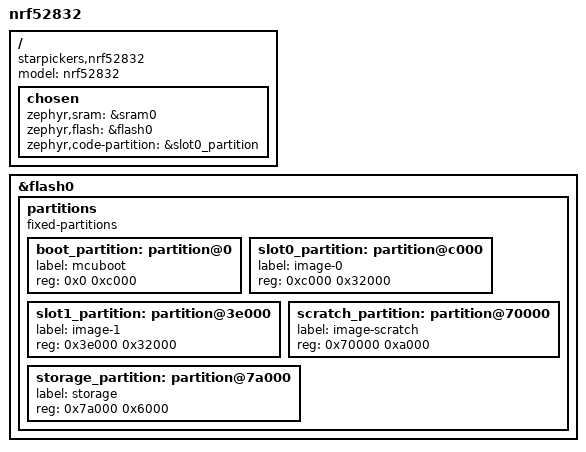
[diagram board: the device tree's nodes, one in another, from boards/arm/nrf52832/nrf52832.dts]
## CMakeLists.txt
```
cmake_minimum_required(VERSION 3.20.0)
find_package(Zephyr REQUIRED HINTS $ENV{ZEPHYR_BASE})

project(Firmware_TEST_IoT)

target_sources(app PRIVATE src/main.cpp
    src/EC21V2.cpp
    src/UARTE.cpp
    src/RTC.cpp)

target_include_directories(app PRIVATE src/)
```

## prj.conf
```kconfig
# General Configurations
CONFIG_CPP=y
CONFIG_NFCT_PINS_AS_GPIOS=y
CONFIG_GPIO_AS_PINRESET=n

# Debugging Configurations
CONFIG_CONSOLE=y
CONFIG_USE_SEGGER_RTT=y
CONFIG_RTT_CONSOLE=y
```

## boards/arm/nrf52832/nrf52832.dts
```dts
// Copyright (c) 2024 Nordic Semiconductor ASA
// SPDX-License-Identifier: Apache-2.0

/dts-v1/;
#include <nordic/nrf52832_qfaa.dtsi>

/ {
	model = "nrf52832";
	compatible = "starpickers,nrf52832";

	chosen {
		zephyr,sram = &sram0;
		zephyr,flash = &flash0;
		zephyr,code-partition = &slot0_partition;
	};
};

&flash0 {
	partitions {
		compatible = "fixed-partitions";
		#address-cells = <1>;
		#size-cells = <1>;

		boot_partition: partition@0 {
			label = "mcuboot";
			reg = <0x0 0xc000>;
		};
		slot0_partition: partition@c000 {
			label = "image-0";
			reg = <0xc000 0x32000>;
		};
		slot1_partition: partition@3e000 {
			label = "image-1";
			reg = <0x3e000 0x32000>;
		};
		scratch_partition: partition@70000 {
			label = "image-scratch";
			reg = <0x70000 0xa000>;
		};
		storage_partition: partition@7a000 {
			label = "storage";
			reg = <0x7a000 0x6000>;
		};
	};
};
```

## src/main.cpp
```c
#include <zephyr/kernel.h>
#include <EC21V2.h>
#include <UARTE.h>
#include <RTC.h>

/* GPIO Pin 설정 */
#define GPIO_LED_RED        22
#define GPIO_LED_GREEN      23
#define GPIO_LED_BLUE       24
#define GPIO_EXT_PWR        2

/* LTE 모뎀 핀 설정 */
#define GPIO_LTE_PIN_DISABLE    7
#define GPIO_LTE_PIN_WAKEUP     8
#define GPIO_LTE_PIN_PWRKEY     25
#define GPIO_LTE_PIN_RESET      26
#define GPIO_LTE_UART_RX        10
#define GPIO_LTE_UART_TX        9

// External Module Library
UARTE uarte;
EC21 lte;
RTC rtc;
EC21_DEVICE_INFO ec21_device_info;
extern bool getmes;

// External Handler
void EC21_EventHandler(uint16_t EC21_EVENT_TYPE);
void EC21_ErrorHandler(uint16_t EC21_ERROR_CODE);

// 인터럽트 핸들러
void RTC2_IRQHandler();
void GPIOTE_IRQHandler();

int main(void)
{
        // GNSS 초기화
        NRF_GPIO->DIRSET = (1 << GPIO_LED_RED) | (1 << GPIO_LED_GREEN) | (1 << GPIO_LED_BLUE);
        NRF_GPIO->OUTSET = (1 << GPIO_LED_RED) | (1 << GPIO_LED_GREEN) | (1 << GPIO_LED_BLUE);

        // 초기화 함수
        RTC_CONFIG rtc_config = {
             .channel = RTC2,
             .prescaler = 32            // 99.9Hz   
        };
        rtc.Init(rtc_config);
        rtc.setEvent(RTC_INTERRUPT_COMPARE0);
        rtc.setInterrupt(RTC_INTERRUPT_COMPARE0);
        IRQ_DIRECT_CONNECT(RTC2_IRQn, 0, RTC2_IRQHandler, 0);
        irq_enable(RTC2_IRQn);
        rtc.Start();
        
        // NFC핀을 GPIO로 변환
        NRF_UICR->NFCPINS = 0x00;

        // LTE 모뎀 초기화
        UARTE_CONFIG config_uarte = {
                .PIN_RX = GPIO_LTE_UART_RX,
                .PIN_TX = GPIO_LTE_UART_TX,
                .BAUD = UARTE_BAUDRATE_115200,
        };
        uarte.Init(config_uarte);
        EC21_CONFIG config_lte = {
                .uarte = uarte,
                .rtc = rtc,
                .pin_pwr = GPIO_LTE_PIN_PWRKEY,
                .pin_reset = GPIO_LTE_PIN_RESET,
                .pin_wakeup = GPIO_LTE_PIN_WAKEUP,
                .pin_disable = GPIO_LTE_PIN_DISABLE,
        };
        lte.Init(config_lte);
        printk("LTE modem initialized.\n");     

        // RESET핀을 GPIO로 설정
        NRF_NVMC->CONFIG = NVMC_CONFIG_WEN_Wen << NVMC_CONFIG_WEN_Pos; // Write Enable
        while (NRF_NVMC->READY == NVMC_READY_READY_Busy){}
        NRF_UICR->PSELRESET[0] = 1 << 31;
        while (NRF_NVMC->READY == NVMC_READY_READY_Busy){}
        NRF_UICR->PSELRESET[1] = 1 << 31;
        while (NRF_NVMC->READY == NVMC_READY_READY_Busy){}
        NRF_NVMC->CONFIG = NVMC_CONFIG_WEN_Ren << NVMC_CONFIG_WEN_Pos; // Read-only Enable
        while (NRF_NVMC->READY == NVMC_READY_READY_Busy){}
        
        // LTE 모뎀 Power On
        lte.Reset();
        k_msleep(200);
        lte.powerOn();

        // GPIOTE Event 및 Interrupt 설정
        // 풀업 설정
        NRF_GPIO->PIN_CNF[21] = 0x0C;
        NRF_GPIOTE->CONFIG[0] = 0x01 | (21 << 8) | (0x02 << 16);
        NRF_GPIOTE->INTENSET = 0x01;
        IRQ_DIRECT_CONNECT(GPIOTE_IRQn, 0, GPIOTE_IRQHandler, 0);
        irq_enable(GPIOTE_IRQn);

        // NVIC 활성화
        NVIC_SetPriority(GPIOTE_IRQn, 5);
        NVIC_EnableIRQ(GPIOTE_IRQn);

        printk("GPIOTE Set.\n");
        while(true){
                k_usleep(10);
        }
        return 0;
}

void EC21_EventHandler(uint16_t EC21_EVENT_TYPE){
        // EC21 이벤트 핸들러
        switch(EC21_EVENT_TYPE){
                case EC21_EVENT_POWERON:
                        // 모뎀의 전원이 켜졌을 때 동작
                        // LED 주황색으로 수정
                        printk("LTE modem power activated.\n");
                        NRF_GPIO->OUTCLR = (1 << GPIO_LED_GREEN);

                        // Echo Off
                        lte.setEcho(false);
                break;
                case EC21_EVENT_ECHO_OFF:
                        // Echo Off 이벤트 동작
                        printk("Echo Off events\n");

                        // 기본 정보 체크
                        ec21_device_info = lte.getDeviceInfo();
                        if(strlen(ec21_device_info.imei) < 1){
                                // IMEI 정보가 없으므로 읽어옴
                                printk("No IMEI information. Query IMEI.\r\n");
                                lte.getImei();
                        }
                break;
                
                case EC21_EVENT_CAPTURE_IMEI:
                        // IMEI값 취득함
                        lte.clearLastQueary();
                        ec21_device_info = lte.getDeviceInfo();
                        if(strlen(ec21_device_info.imei) < 15){
                                break;
                        }
                        printk("IMEI Captured : %s\n", ec21_device_info.imei);
                        
                        // ICCID값 존재 여부 체크
                        if(strlen(ec21_device_info.iccid) < 1){
                                // ICCID 값이 없으므로 읽어옴
                                printk("No ICCID information. Query ICCID.\r\n");
                                lte.getIccid();
                        }
                break;
                case EC21_EVENT_CAPTURE_ICCID:
                        // ICCID값 취득 이벤트
                        lte.clearLastQueary();
                        ec21_device_info = lte.getDeviceInfo();
                        if(strlen(ec21_device_info.iccid) < 20){
                                break;
                        }
                        printk("ICCID Captured : %s\n", ec21_device_info.iccid);

                        // IMSI값 존재 여부 체크
                        if(strlen(ec21_device_info.imsi) < 1){
                                // ICCID 값이 없으므로 읽어옴
                                printk("No IMSI information. Query ICCID.\r\n");
                                lte.getImsi();
                        }
                break;
                case EC21_EVENT_CAPTURE_IMSI:
                        // IMSI값 취득 이벤트
                        lte.clearLastQueary();
                        ec21_device_info = lte.getDeviceInfo();
                        if(strlen(ec21_device_info.iccid) < 20){
                                break;
                        }
                        printk("IMSI Captured : %s\n", ec21_device_info.imsi);
                break;
        }
}
void EC21_ErrorHandler(uint16_t EC21_ERROR_CODE){

}

void RTC2_IRQHandler(){
        // RTC2 IRQHandler
        if(NRF_RTC2->EVENTS_COMPARE[0] == 1){
                NRF_RTC2->EVENTS_COMPARE[0] = 0;
                NRF_UARTE0->TASKS_STOPRX = 1;
        }
}

void GPIOTE_IRQHandler(){
        // GPIOTE 핸들러 

        int cnt = 0;

        if(NRF_GPIOTE->EVENTS_IN[0] == 1){
                NRF_GPIOTE->EVENTS_IN[0] = 0;
                        /*
                        printk("AT+CFUN=1\n");
                        lte.Query("AT+CFUN=1\r\n");
                        k_busy_wait(2000000);

                        printk("AT+QGPS=1\n");
                        lte.Query("AT+QGPS=1\r\n");
                        k_busy_wait(2000000);

                        ///printk("AT+QCFG=\"band\",F,80A,80A\n");
                        ///lte.Query("AT+QCFG=\"band\",F,80A,80A\r\n");
                        ///k_busy_wait(2000000); 

                        printk("AT+COPS=4,2,\"310410\"\n");
                        lte.Query("AT+COPS=4,2,\"310410\"\r\n");
                        k_busy_wait(2000000);   

                        printk("AT+CREG=2\n");
                        lte.Query("AT+CREG=2\r\n");
                        k_busy_wait(2000000); 

                        printk("AT+QSCLK=0\n");
                        lte.Query("AT+QSCLK=0\r\n");
                        k_busy_wait(2000000);

                        //printk("AT+QCFG=\"powerclass\",1,1\n");
                        //lte.Query("AT+QCFG=\"powerclass\",1,1\r\n");
                        //k_busy_wait(2000000);

                        */
                        //AWS연결
                        printk("AT+CEREG?\n");
                        lte.Query("AT+CEREG?\r\n");
                        k_busy_wait(2000000);
                        
                        printk("AT+QENG=\"servingcell\"\n");
                        lte.Query("AT+QENG=\"servingcell\"\r\n");
                        k_busy_wait(2000000);
                        
                        printk("AT+QIACT=1\n");
                        lte.Query("AT+QIACT=1\r\n");
                        k_busy_wait(2000000);
                        
                        printk("AT+CGPADDR=1\n");
                        lte.Query("AT+CGPADDR=1\r\n");
                        k_busy_wait(2000000);
                        
                        printk("AT+QPING=1,\"a3ovp7i619ec6q-ats.iot.us-east-1.amazonaws.com\"\n");
                        lte.Query("AT+QPING=1,\"a3ovp7i619ec6q-ats.iot.us-east-1.amazonaws.com\"\r\n");
                        k_busy_wait(4000000);
                        
                        printk("AT+QFLST=\"*\"\n");
                        lte.Query("AT+QFLST=\"*\"\r\n");
                        k_busy_wait(2000000);
                        
                        printk("AT+QMTCFG=\"recv/mode\",0,0,1\n");
                        lte.Query("AT+QMTCFG=\"recv/mode\",0,0,1\r\n");
                        k_busy_wait(2000000);
                        
                        printk("AT+QMTCFG=\"ssl\",0,1,2\n");
                        lte.Query("AT+QMTCFG=\"ssl\",0,1,2\r\n");
                        k_busy_wait(2000000);
                        
                        printk("AT+QSSLCFG=\"cacert\",2,\"cacert.pem\"\n");
                        lte.Query("AT+QSSLCFG=\"cacert\",2,\"cacert.pem\"\r\n");
                        k_busy_wait(2000000);
                        
                        printk("AT+QSSLCFG=\"clientcert\",2,\"client.pem\"\n");
                        lte.Query("AT+QSSLCFG=\"clientcert\",2,\"client.pem\"\r\n");
                        k_busy_wait(2000000);
                        
                        printk("AT+QSSLCFG=\"clientkey\",2,\"user_key.pem\"\n");
                        lte.Query("AT+QSSLCFG=\"clientkey\",2,\"user_key.pem\"\r\n");
                        k_busy_wait(2000000);
                        
                        printk("AT+QSSLCFG=\"seclevel\",2,2\n");
                        lte.Query("AT+QSSLCFG=\"seclevel\",2,2\r\n");
                        k_busy_wait(2000000);
                        
                        printk("AT+QSSLCFG=\"sslversion\",2,4\n");
                        lte.Query("AT+QSSLCFG=\"sslversion\",2,4\r\n");
                        k_busy_wait(2000000);

                        printk("AT+QSSLCFG=\"ciphersuite\",2,0xFFFF\n");
                        lte.Query("AT+QSSLCFG=\"ciphersuite\",2,0xFFFF\r\n");
                        k_busy_wait(2000000);
                        
                        printk("AT+QSSLCFG=\"ignorelocaltime\",2,1\n");
                        lte.Query("AT+QSSLCFG=\"ignorelocaltime\",2,1\r\n");
                        k_busy_wait(2000000);
                        
                        printk("AT+QMTOPEN=0,\"a3ovp7i619ec6q-ats.iot.us-east-1.amazonaws.com\",8883\n");
                        lte.Query("AT+QMTOPEN=0,\"a3ovp7i619ec6q-ats.iot.us-east-1.amazonaws.com\",8883\r\n");
                        k_busy_wait(2000000);
                        
                        printk("AT+QMTCONN=0,\"smartKit001\"\n");
                        lte.Query("AT+QMTCONN=0,\"smartKit001\"\r\n");
                        k_busy_wait(2000000);

                        //연결 완료
                        printk("AWS Connected\n");

                        printk("AT+QMTPUBEX=0,1,1,0,\"aws/smartKit001/data/report/message\",23\n");
                        lte.Query("AT+QMTPUBEX=0,1,1,0,\"aws/smartKit001/data/report/message\",23\r\n");
                        k_busy_wait(2000000);
                        
                        printk("{\"message\": \"TEST\"}\n");
                        lte.Query("{\"message\": \"TEST\"}\r\n");
                        k_busy_wait(2000000);
                        
                        //송신 테스트 완료
                        printk("AWS message sended\n");

                        // 저전력 모드로 진입
                        //NRF_UART0->TASKS_STOPTX = 1; // UART 송신 중지
                        //NRF_UART0->TASKS_STOPRX = 1; // UART 수신 중지
                        //NRF_UART0->ENABLE = 0; // UART 비활성화

                        printk("Low power mode starting...\n");

                        /*
                        printk("AT+QCFG=\"powerclass\",1,0\n");
                        lte.Query("AT+QCFG=\"powerclass\",1,0\r\n");
                        k_busy_wait(2000000);
                        */

                        NRF_SPI0->ENABLE = 0; // SPI 비활성화
                        printk("SPI unactivated\n");

                        NRF_TWI0->ENABLE = 0; // TWI(I2C) 비활성화
                        printk("TWI unactivated\n");

                        NRF_SAADC->ENABLE = 0; // ADC 비활성화
                        printk("ADC unactivated\n");

                        NRF_TIMER0->TASKS_STOP = 1; // 타이머0 중지
                        printk("Timer0 unactivated\n");

                        NRF_TIMER1->TASKS_STOP = 1; // 타이머1 중지
                        printk("Timer1 unactivated\n");

                        NRF_TIMER2->TASKS_STOP = 1; // 타이머2 중지
                        printk("Timer2 unactivated\n");

                        // 저전력 모드 활성화
                        NRF_POWER->TASKS_LOWPWR = 1;
                        printk("TASK_LOWPWR\n");

                        /*
                        printk("AT+QGPSEND\n");
                        lte.Query("AT+QGPSEND\r\n");
                        k_busy_wait(2000000);

                        printk("AT+CREG=0\n");
                        lte.Query("AT+CREG=0\r\n");
                        k_busy_wait(2000000);

                        printk("AT+COPS=0\n");
                        lte.Query("AT+COPS=0\r\n");
                        k_busy_wait(2000000);

                        printk("AT+QCFG=\"band\",F,1,1\n");
                        lte.Query("AT+QCFG=\"band\",F,1,1\r\n");
                        k_busy_wait(2000000); 
                        */

                         // LTE 및 GNSS 저전력 모드 활성화
                        printk("AT+QSCLK=1\n");
                        lte.Query("AT+QSCLK=1\r\n"); // 저전력 모드 활성화 명령어
                        k_busy_wait(2000000);

                        //lte.Query("AT+QGPSCFG=\"gnssconfig\",0\r\n"); // GNSS 저전력 모드 활성화
                        //k_busy_wait(2000000);
                        //printk("21\n");
                        printk("AT+QGPS=1\n");
                        printk("GNSS init\n");
                        lte.Query("AT+QGPS=1\r\n");//GNSS 초기화
                        k_busy_wait(2000000); 

                        printk("AT+QGPSEND\n");
                        printk("GNSS unactivated\n");
                        lte.Query("AT+QGPSEND\r\n"); // GNSS 비활성화
                        k_busy_wait(2000000);

                        printk("Low power mode on\n");

                        while (cnt<10)
                        {
                                printk("Enter Loop %d\n",cnt);
                                lte.Query("AT+QMTSUB=0,1,\"aws/smartKit001/data/report/message\",1\r\n");
                                k_busy_wait(10000000);
                                cnt++;
                                if(getmes == true){
                                        printk("Message interrupted!\n");
                                        break;
                                }
                        }
                        getmes = false;
                        
                        cnt = 0;

                        printk("Low Power mode exiting...\n");
                
                     // 외부 신호에 의해 정상 모드로 복귀
                        //NRF_UART0->TASKS_STOPTX = 1; // UART 송신 중지
                        //NRF_UART0->TASKS_STOPRX = 1; // UART 수신 중지
                        //NRF_UART0->ENABLE = 1; // UART 활성화
                        //NRF_UART0->TASKS_STARTRX = 1; // UART 수신 시작
                        //NRF_UART0->TASKS_STARTTX = 1; // UART 송신 시작
                        NRF_SPI0->ENABLE = 1; // SPI 활성화
                        printk("SPI activated\n");
                        
                        NRF_TWI0->ENABLE = 1; // TWI(I2C) 활성화
                        printk("TWI activated\n");

                        NRF_SAADC->ENABLE = 1; // ADC 활성화
                        printk("ADC activated\n");

                        NRF_TIMER0->TASKS_START = 1; // 타이머0 시작
                        printk("Timer0 activated\n");

                        NRF_TIMER1->TASKS_START = 1; // 타이머1 시작
                        printk("Timer1 activated\n");

                        NRF_TIMER2->TASKS_START = 1; // 타이머2 시작
                        printk("Timer2 activated\n");


                        printk("AT+QCFG=\"powerclass\",1,0\n");
                        lte.Query("AT+QCFG=\"powerclass\",1,0\r\n");

                        // LTE 및 GNSS 정상 모드 복귀
                        printk("AT+QSCLK=0\n");
                        lte.Query("AT+QSCLK=0\r\n"); // 저전력 모드 해제 명령어
                        k_busy_wait(2000000);
                        
                        printk("AT+QGPS=1\n");
                        printk("GNSS activated\n");
                        lte.Query("AT+QGPS=1\r\n"); // GNSS 활성화
                        k_busy_wait(2000000);

                        printk("Low power mode off\n");
        }
}
```

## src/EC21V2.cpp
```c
#include <EC21V2.h>

/* Global Variables */
static uint8_t rxBuffer[255] = {0};
char EC21::lastQuery[255] = {0};
uint16_t EC21::error_code = 0;
char Hello[6]="Hello";
bool getmes = false;

/* Global Functions */
EC21_CONFIG EC21::CONFIG;
EC21_DEVICE_INFO device_info;
extern void EC21_EventHandler(uint16_t EC21_EVENT_TYPE);
extern void EC21_ErrorHandler(uint16_t EC21_ERROR_CODE);

/* EC21 초기화 함수 */
void EC21::Init(EC21_CONFIG ec21_config){
    // 설정값 초기화 및 복사
    memset(&CONFIG, 0x00, sizeof(CONFIG));
    memcpy(&CONFIG, &ec21_config, sizeof(ec21_config));
    
    // GPIO 활성화
    NRF_GPIO->DIRSET = (1 << CONFIG.pin_pwr) | (1 << CONFIG.pin_reset) | (1 << CONFIG.pin_disable) | (1 << CONFIG.pin_wakeup);

    // UARTE 초기화
    CONFIG.uarte.setInterrupt(UARTE_INTERRUPT_RXDRDY | UARTE_INTERRUPT_ENDRX | UARTE_INTERRUPT_RXTO);
    CONFIG.uarte.setShorts(UARTE_SHORTS_ENDRX_STARTRX);
    IRQ_DIRECT_CONNECT(UARTE0_UART0_IRQn, 0, UARTE_IRQHandler, 0);
    irq_enable(UARTE0_UART0_IRQn);
    NRF_UARTE0->RXD.PTR = (uint32_t)rxBuffer;
    CONFIG.uarte.startRx(255);
}

bool EC21::Query(const char *cmd, ...){
    char temp[255] = {0};
    va_list ap;
    va_start(ap, cmd);
    vsprintf(temp, cmd, ap);
    va_end(ap);
    
    // 현재 명령어 저장
    if(strncmp(temp, "A/", 2) != 0){
        memset(lastQuery, 0x00, 255);
        strcpy(lastQuery, temp);
    }
    CONFIG.uarte.Write((uint8_t *)temp, strlen(temp));
    return true;
}

void EC21::powerOn(){
    // 모뎀 파워 온
    NRF_GPIO->OUTSET = (1 << CONFIG.pin_pwr);
    k_busy_wait(200000);
    NRF_GPIO->OUTCLR = (1 << CONFIG.pin_pwr);
}

void EC21::Reset(){
    // 모뎀 리셋
    NRF_GPIO->OUTSET = (1 << CONFIG.pin_reset);
    k_busy_wait(200000);
    NRF_GPIO->OUTCLR = (1 << CONFIG.pin_reset);
}

void EC21::retryQuery(){
    // 직전 명령어 재시도
    Query("A/\r\n");
}

void EC21::getSimStatus(){
    // SIM 상태 쿼리
    Query("AT+CPIN?\r\n");
}

void EC21::UARTE_IRQHandler(){
    if(NRF_UARTE0->EVENTS_RXDRDY == 1){
        NRF_UARTE0->EVENTS_RXDRDY = 0;
        CONFIG.rtc.setCompare(RTC_COMPARE0, CONFIG.rtc.getCounter() + UARTE_TIMEOUT);
    }
    if(NRF_UARTE0->EVENTS_ENDRX == 1){
        NRF_UARTE0->EVENTS_ENDRX = 0;
        printk("%s\n", rxBuffer); //주석 해제 처리
        if (strstr((char *)rxBuffer,Hello)!=NULL)
        {
            getmes = true;
        }
        
        parseCommand((const char *)rxBuffer);
        memset(rxBuffer, 0x00, 255);
    }
    if(NRF_UARTE0->EVENTS_RXTO == 1){
        
        NRF_UARTE0->EVENTS_RXTO = 0;
        NRF_UARTE0->TASKS_FLUSHRX = 1;
        printk("EVENTS_RXTO\n");
    }
}

void EC21::parseCommand(const char *cmd){
    // 파싱 함수
    char *temp_ptr, *temp;

    temp = strtok_r((char *)cmd, "\r\n", &temp_ptr);
    while(temp != NULL){
        printk("Temp : %s\r\n", temp);
        
        if(strncmp(temp, "+QIND: \"POWER\",1", 15) == 0){
            // Power On 이벤트
            EC21_EventHandler(EC21_EVENT_POWERON);
        }else if(strncmp(temp, "RDY", 3) == 0){
            // Power On 이벤트
            EC21_EventHandler(EC21_EVENT_POWERON);
        }else if(strncmp(temp, "ATE1", 4) == 0){
            // Echo on 이벤트
            EC21_EventHandler(EC21_EVENT_ECHO_ON);
        }else if(strncmp(temp, "+QIND: PB DONE", 14) == 0){
            // Strange
            //EC21_EventHandler(EC21_EVENT_SIM_NORMAL);
        }else if(strncmp(temp, "ATE0", 4) == 0){
            // Echo on 이벤트
            EC21_EventHandler(EC21_EVENT_ECHO_OFF);
        }else if(strncmp(temp, "+CPIN: READY", 12) == 0){
            // USIM 인식 확인
            EC21_EventHandler(EC21_EVENT_SIM_NORMAL);
        }else if(strncmp(temp, "+CPIN: NOT INSERTED", 19) == 0){
            // USIM 인식 확인
            EC21_EventHandler(EC21_EVENT_POWERON);
        }else if(strncmp(temp, "+CME", 4) == 0){
            // CME 에러 체크
            temp = strtok_r(temp, " ", &temp_ptr);
            temp = strtok_r(NULL, " ", &temp_ptr);
            temp = strtok_r(NULL, "\r\n", &temp_ptr);
            error_code = atoi(temp);
            EC21_ErrorHandler(error_code);
        }else if(strncmp(temp, "+QCCID", 6) == 0){
            // ICCID 값 캡쳐 및 저장
            temp = strtok_r(temp, " ", &temp_ptr);
            temp = strtok_r(NULL, "\r\n", &temp_ptr);
            strcpy(device_info.iccid, temp);
            EC21_EventHandler(EC21_EVENT_CAPTURE_ICCID);
        }else if((strncmp(temp, "+CREG", 5) == 0) && (strncmp(lastQuery, "AT+CREG?", 8) == 0)){
            // 네트워크 등록 체크
            temp = strtok_r(temp, ",", &temp_ptr);
            temp = strtok_r(NULL, "\r\n", &temp_ptr);
            uint8_t netStatus = atoi(temp);
            switch(netStatus){
                case 1:
                    EC21_EventHandler(EC21_EVENT_NETWORK_REGISTERED);
                break;
                case 2:
                    EC21_EventHandler(EC21_EVENT_NETWORK_NOT_REGISTERED);
                break;
                case 3:
                    EC21_EventHandler(EC21_EVENT_NETWORK_REGISTRATION_DENIED);
                break;
                case 4:
                    EC21_EventHandler(EC21_EVENT_NETWORK_REGISTRATION_UNKNOWN);
                break;
                case 5:
                    EC21_EventHandler(EC21_EVENT_NETWORK_REGISTERED_ROAMING);
                break;
                default:
                    EC21_EventHandler(EC21_EVENT_NETWORK_NOT_REGISTERED);
                break;
            }
        }else if(strncmp(temp, "+QLTS", 5) == 0){
            // 시스템 날짜 및 시간 캡쳐
            // 읽은 날짜 및 시간을 Unix epoch 값으로 변환
            struct tm t;
            temp = strtok_r(temp, "\"", &temp_ptr);
            temp = strtok_r(NULL, "/", &temp_ptr);
            t.tm_year = atoi(temp)-1900;
            temp = strtok_r(NULL, "/", &temp_ptr);
            t.tm_mon = atoi(temp)-1;
            temp = strtok_r(NULL, ",", &temp_ptr);
            t.tm_mday = atoi(temp);
            temp = strtok_r(NULL, ":", &temp_ptr);
            t.tm_hour = atoi(temp);
            temp = strtok_r(NULL, ":", &temp_ptr);
            t.tm_min = atoi(temp);
            temp = strtok_r(NULL, "+", &temp_ptr);
            t.tm_sec = atoi(temp);
            device_info.epoch = timeutil_timegm64(&t);
            EC21_EventHandler(EC21_EVENT_CAPTURE_SYSTIME);
        }else if(strncmp(temp, "+QHTTPPOST", 10) == 0){
            // QHTTPPOST Check
            temp = strtok_r(temp, ":", &temp_ptr);
            temp = strtok_r(NULL, ",", &temp_ptr);
            int16_t returnCode = atoi(temp);
            temp = strtok_r(NULL, ",", &temp_ptr);
            int16_t responseCode = atoi(temp);
            temp = strtok_r(NULL, ",", &temp_ptr);
            int16_t contentsLength = atoi(temp);
            if(returnCode == 702){
                // HTTP Timeout
                EC21_ErrorHandler(EC21_HTTP_ERROR_GENERAL);
            }else if(returnCode == 703){
                // HTTP Busy
                EC21_ErrorHandler(EC21_CME_ERROR_HTTP_BUSY);
            }else if(returnCode == 704){
                // HTTP UART Busy
                EC21_ErrorHandler(EC21_HTTP_ERROR_GENERAL);
            }else if(responseCode == 403){
                // 서버 주소 에러
                EC21_ErrorHandler(EC21_HTTP_RESPONSE_403);
            }else if(contentsLength == 8){
                // 재부팅용
                EC21_EventHandler(EC21_EVENT_REMOTE_REBOOT);
            }else{
                EC21_EventHandler(EC21_EVENT_QHTTPPOST);
            }
        }else if(strncmp(temp, "OK", 2) == 0){
            // OK 명령 파싱
            if(strcmp(lastQuery, "AT+QIACT=1\r\n") == 0){
                // Activate PDP Context 명령
                EC21_EventHandler(EC21_EVENT_QI_ACTIVATED);
            }else if(strncmp(lastQuery, "AT+QHTTPCFG", 11) == 0){
                // QHTTPCFG 설정 OK
                EC21_EventHandler(EC21_EVENT_QHTTPCFG_SET);
            }else if(strncmp(lastQuery, "http", 4) == 0){
                // http url 설정
                EC21_EventHandler(EC21_EVENT_QHTTPURL_SET);
            }else if(strncmp(lastQuery, "AT+QIDEACT", 10) == 0){
                Query("AT+QIACT=1\r\n");
            }else{
                //temp = strtok_r(NULL, ":", &temp_ptr);
                //printk("Query OK : %s\r\n", temp);
            }
        }else if(strncmp(temp, "CONNECT", 7) == 0){
            // CONNECT 명령 파싱
            if(strncmp(lastQuery, "AT+QHTTPURL", 11) == 0){
                Query("%s\r\n", device_info.urls);
            }else if(strncmp(lastQuery, "AT+QHTTPPOST", 12) == 0){
                EC21_EventHandler(EC21_EVENT_QHTTPPOST_SET);
            }else{
                //printk("Query Connect : %s", temp);
            }
        }else if(strncmp(temp, "+QIND: \"FOTA\",\"START\"", 21) == 0){
            // FOTA START 관련 처리
            EC21_EventHandler(EC21_EVENT_FOTA_START);
        }else if(strncmp(temp, "+QIND: \"FOTA\",\"END\"", 17) == 0){
            // FOTA END 관련 처리
            EC21_EventHandler(EC21_EVENT_FOTA_END);
        }else if(strncmp(temp, "+QIND: \"FOTA\"", 13) == 0){
            // FOTA PROGRESS 관련 처리
            EC21_EventHandler(EC21_EVENT_FOTA_PROGRESS);
        }else if(strncmp(temp, "+QKTFOTA: 200", 13) == 0){
            // KT FOTA 처리
            EC21_EventHandler(EC21_EVENT_FOTA_KT);
        }else if(strncmp(temp, "+QURC: \"DMC-APN\"", 16) == 0){
            // APN 변경시 동작
            EC21_EventHandler(EC21_EVENT_APN_CHANGED);
        }else if(strncmp(temp, "ERROR", 5) == 0){
            // 에러 동작
            EC21_ErrorHandler(EC21_GENERAL_ERROR);
        }else{
            // 별도의 AT 커맨드 표기 없는 리턴 값 분류
            if((strcmp(lastQuery, "AT+GSN\r\n") == 0) && (strncmp(temp, "86", 2) == 0)){
                // IMEI 쿼리
                temp = strtok_r(temp, "\r\n", &temp_ptr);
                strcpy(device_info.imei, temp);
                EC21_EventHandler(EC21_EVENT_CAPTURE_IMEI);
            }else if((strcmp(lastQuery, "AT+CIMI\r\n") == 0) && (temp[0] >= 0x30 && temp[0] <= 0x39)){
                // IMSI 쿼리
                temp = strtok_r(temp, "\r\n", &temp_ptr);
                strcpy(device_info.imsi, temp);
                EC21_EventHandler(EC21_EVENT_CAPTURE_IMSI);
            }else{
            //printk("TEST : %s", temp);
            }
        }
        temp = strtok_r(NULL, "\r\n", &temp_ptr);
    };
}

uint16_t EC21::getErrorCode(){
    return error_code;
}

EC21_DEVICE_INFO EC21::getDeviceInfo(){
    // ICCID, IMEI, IMSI 값 읽어오는 함수
    return device_info;
}

tm EC21::getDatetime(uint64_t time_elapsed){
    // 시간 계산
    time_t temp = device_info.epoch + time_elapsed;
    struct tm output = {0};
    gmtime_r(&temp, &output);
    return output;
}

void EC21::getIccid(){
    // ICCID 값 쿼리 함수
    Query("AT+QCCID\r\n");
}
void EC21::getImei(){
    // IMEI 값 쿼리 함수
    Query("AT+GSN\r\n");
}
void EC21::getImsi(){
    // IMSI 값 쿼리 함수
    Query("AT+CIMI\r\n");
}

void EC21::getNetworkDatetime(){
    // 시스템 날짜 및 시간 쿼리 함수
    Query("AT+QLTS=2\r\n");
}

void EC21::setEcho(bool enable){
    if(enable){
        Query("ATE1\r\n");
    }else{
        Query("ATE0\r\n");
    }
}

void EC21::setHttpBody(){
    // HTTP Body 형식 지정
    Query("AT+QHTTPCFG=\"contenttype\",4\r\n");
}

void EC21::setHttpUrls(const char *urls, ...){
    // HTTP Endpoint 설정
    memset(device_info.urls, 0x00, 255);
    va_list ap;
    va_start(ap, urls);
    vsprintf(device_info.urls, urls, ap);
    va_end(ap);

    if(strncmp(device_info.urls, "http://", 7) == 0){
        // URL 설정 쿼리
        Query("AT+QHTTPURL=%d\r\n", strlen(device_info.urls));
    }else if(strncmp(device_info.urls, "https://", 8) == 0){
        // URL 설정 쿼리
        Query("AT+QHTTPURL=%d\r\n", strlen(device_info.urls));
    }else{
        printk("Wrong URL set.\r\n");
    }
}

void EC21::setHttpPost(uint16_t data_length){
    // HTTP Post 보내는 함수
    Query("AT+QHTTPPOST=%d,%d,%d\r\n", data_length, EC21_TIMEOUT, EC21_TIMEOUT);
}

void EC21::enablePDP(){
    // Activate PDP Context
    Query("AT+QIACT=1\r\n");
}
void EC21::disablePDP(){
    // Deactivate PDP Context
    Query("AT+QIDEACT=1\r\n");
}

void EC21::checkNetworkRegistration(){
    // 네트워크 등록 체크
    Query("AT+CREG?\r\n");
}

void EC21::clearDeviceInfo(){
    // 장치 정보 초기화
    memset(device_info.iccid, 0x00, sizeof(char *));
    memset(device_info.imei, 0x00, sizeof(char *));
    memset(device_info.imsi, 0x00, sizeof(char *));
    memset(lastQuery, 0x00, 255);
}

void EC21::clearLastQueary(){
    memset(lastQuery, 0x00, 255);
}
```

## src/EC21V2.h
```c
/*
        EC21 Series Module Library V2
        Author : Seonguk Jeong
        Created at : 2024-05-02
        Updated at : 2024-05-02
        Target : Quectel EC21
*/
#include <UARTE.h>
#include <RTC.h>
#include <stdlib.h>
#include <stdio.h>
#include <time.h>
#include <zephyr/sys/timeutil.h>

/* EC21 Modem Event */
#define EC21_EVENT_POWERON                          0x0001
#define EC21_EVENT_POWEROFF                         0x0002
#define EC21_EVENT_SIM_NORMAL                       0x0003
#define EC21_EVENT_SIM_ERROR                        0x0004
#define EC21_EVENT_ECHO_ON                          0x0005
#define EC21_EVENT_ECHO_OFF                         0x0006
#define EC21_EVENT_CAPTURE_ICCID                    0x0007
#define EC21_EVENT_CAPTURE_IMEI                     0x0008
#define EC21_EVENT_CAPTURE_IMSI                     0x0009
#define EC21_EVENT_CAPTURE_SYSTIME                  0x000A
#define EC21_EVENT_QI_ACTIVATED                     0x000B
#define EC21_EVENT_QI_DEACTIVATED                   0x000C
#define EC21_EVENT_QHTTPCFG_SET                     0x000D
#define EC21_EVENT_QHTTPURL_SET                     0x000E
#define EC21_EVENT_QHTTPPOST_SET                    0x000F
#define EC21_EVENT_QHTTPPOST                        0x0010
#define EC21_EVENT_NETWORK_NOT_REGISTERED           0x0011
#define EC21_EVENT_NETWORK_REGISTERED               0x0012
#define EC21_EVENT_NETWORK_REGISTRATION_DENIED      0x0013
#define EC21_EVENT_NETWORK_REGISTRATION_UNKNOWN     0x0014
#define EC21_EVENT_NETWORK_REGISTERED_ROAMING       0x0015
#define EC21_EVENT_FOTA_START                       0x0016
#define EC21_EVENT_FOTA_PROGRESS                    0x0017
#define EC21_EVENT_FOTA_END                         0x0018
#define EC21_EVENT_FOTA_KT                          0x0019
#define EC21_EVENT_APN_CHANGED                      0x0020
#define EC21_EVENT_REMOTE_REBOOT                    0x0FFF

/* EC21 CME Error Code */
#define EC21_CME_ERROR_SIM_NOT_INSERTED             10
#define EC21_CME_ERROR_SIM_PIN_REQUIRED             11
#define EC21_CME_ERROR_SIM_PUK_REQUIRED             13
#define EC21_CME_ERROR_SIM_FAILURE                  14
#define EC21_CME_ERROR_SIM_BUSY                     15
#define EC21_CME_ERROR_SIM_WRONG                    16
#define EC21_HTTP_RESPONSE_403                      403
#define EC21_HTTP_ERROR_GENERAL                     700
#define EC21_CME_ERROR_HTTP_UNKNOWN                 701
#define EC21_CME_ERROR_HTTP_BUSY                    703
#define EC21_CME_ERROR_HTTP_DNS_ERROR               714
#define EC21_CME_ERROR_HTTP_CONNECT_ERROR           716
#define EC21_HTTP_ERROR_TIMEOUT                     702
#define EC21_HTTP_ERROR_BUSY                        703
#define EC21_GENERAL_ERROR                          900

/* EC21 기본 설정 */
#define UARTE_TIMEOUT 50
#define EC21_TIMEOUT 5

struct EC21_CONFIG{
    UARTE uarte;
    RTC rtc;
    uint8_t pin_pwr;
    uint8_t pin_reset;
    uint8_t pin_wakeup;
    uint8_t pin_disable;
};
typedef struct _EC21_DEVICE_INFO{
    char imei[16] = {0};
    char imsi[16] = {0};
    char iccid[21] = {0};
    uint64_t epoch = 0;
    char urls[255] = {0};
}EC21_DEVICE_INFO;
class EC21{
    private:
        static void UARTE_IRQHandler();
        static EC21_CONFIG CONFIG;
        static uint16_t error_code;
        static char lastQuery[255];
        static void parseCommand(const char *cmd);
    public:
        void Init(EC21_CONFIG ec21_config);
        void powerOn();
        void Reset();
        void retryQuery();
        void getSimStatus();
        uint16_t getErrorCode();
        EC21_DEVICE_INFO getDeviceInfo();
        tm getDatetime(uint64_t time_elapsed);
        void getIccid();
        void getImei();
        void getImsi();
        void getNetworkDatetime();
        void setEcho(bool enable);
        void setHttpBody();
        void setHttpUrls(const char *urls, ...);
        void setHttpPost(uint16_t data_length);
        void enablePDP();
        void disablePDP();
        void checkNetworkRegistration();
        void clearDeviceInfo();
        void clearLastQueary();
        static bool Query(const char *cmd, ...);
        
};
```

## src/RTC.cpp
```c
#include "RTC.h"

void RTC::Init(RTC_CONFIG CONFIG){
    // Low frequency clock 활성화 체크
	if(!(NRF_CLOCK->LFCLKSTAT >> 16) & 0x01){
		NRF_CLOCK->LFCLKSRC = CLOCK_LFCLKSRC_SRC_Xtal;
		NRF_CLOCK->TASKS_LFCLKSTART = 0x01;
		while(!NRF_CLOCK->EVENTS_LFCLKSTARTED){}
	}
    switch(CONFIG.channel){
        case RTC0:
            NRF_RTC0->TASKS_CLEAR = 1;
		    NRF_RTC0->TASKS_STOP = 1;
		    NRF_RTC0->PRESCALER = CONFIG.prescaler;
            break;
        case RTC1:
            NRF_RTC1->TASKS_CLEAR = 1;
		    NRF_RTC1->TASKS_STOP = 1;
		    NRF_RTC1->PRESCALER = CONFIG.prescaler;
            break;
        case RTC2:
            NRF_RTC2->TASKS_CLEAR = 1;
		    NRF_RTC2->TASKS_STOP = 1;
		    NRF_RTC2->PRESCALER = CONFIG.prescaler;
            break;
        default:
            break;
    }
    // 설정 구조체 저장
    memcpy(&CONF, &CONFIG, sizeof(CONFIG));
}

void RTC::Start(){
    switch(CONF.channel){
        case RTC0:
            NRF_RTC0->TASKS_START = 1;
            break;
        case RTC1:
            NRF_RTC1->TASKS_START = 1;
            break;
        case RTC2:
            NRF_RTC2->TASKS_START = 1;
            break;
        default:
            break;
    }
}
void RTC::Stop(){
    switch(CONF.channel){
        case RTC0:
            NRF_RTC0->TASKS_STOP = 1;
            NRF_RTC0->TASKS_CLEAR = 1;
            break;
        case RTC1:
            NRF_RTC1->TASKS_STOP = 1;
            NRF_RTC1->TASKS_CLEAR = 1;
            break;
        case RTC2:
            NRF_RTC2->TASKS_STOP = 1;
            NRF_RTC2->TASKS_CLEAR = 1;
            break;
        default:
            break;
    }
}
void RTC::setInterrupt(uint32_t interrupt){
    switch(CONF.channel){
        case RTC0:
            NRF_RTC0->INTENSET = interrupt;
            NVIC_SetPriority(RTC0_IRQn, 5);
	        NVIC_EnableIRQ(RTC0_IRQn);
            break;
        case RTC1:
            NRF_RTC1->INTENSET = interrupt;
            NVIC_SetPriority(RTC1_IRQn, 5);
	        NVIC_EnableIRQ(RTC1_IRQn);
            break;
        case RTC2:
            NRF_RTC2->INTENSET = interrupt;
            NVIC_SetPriority(RTC2_IRQn, 5);
	        NVIC_EnableIRQ(RTC2_IRQn);
            break;
        default:
            break;
    }
}
void RTC::clearInterrupt(uint32_t interrupt){
    switch(CONF.channel){
        case RTC0:
            NRF_RTC0->INTENCLR = interrupt;
            break;
        case RTC1:
            NRF_RTC1->INTENCLR = interrupt;
            break;
        case RTC2:
            NRF_RTC2->INTENCLR = interrupt;
            break;
        default:
            break;
    }
}
void RTC::setEvent(uint32_t event){
    switch(CONF.channel){
        case RTC0:
            NRF_RTC0->EVTENSET = event;
            break;
        case RTC1:
            NRF_RTC1->EVTENSET = event; 
            break;
        case RTC2:
            NRF_RTC2->EVTENSET = event;
            break;
        default:
            break;
    }
}
void RTC::clearEvent(uint32_t event){
    switch(CONF.channel){
        case RTC0:
            NRF_RTC0->EVTENCLR = event;
            break;
        case RTC1:
            NRF_RTC1->EVTENCLR = event;
            break;
        case RTC2:
            NRF_RTC2->EVTENCLR = event;
            break;
        default:
            break;
    }
}
void RTC::setCompare(uint8_t comp_no, uint32_t cc){
    if(comp_no > 4){
        return;
    }
    switch(CONF.channel){
        case RTC0:
            NRF_RTC0->CC[comp_no] = cc;
            break;
        case RTC1:
            NRF_RTC1->CC[comp_no] = cc;
            break;
        case RTC2:
            NRF_RTC2->CC[comp_no] = cc;
            break;
        default:
            break;
    }
}
uint32_t RTC::getCounter(){
    static uint32_t output=0;
    switch(CONF.channel){
        case RTC0:
            output = NRF_RTC0->COUNTER;
            break;
        case RTC1:
            output = NRF_RTC1->COUNTER;
            break;
        case RTC2:
            output = NRF_RTC2->COUNTER;
            break;
        default:
            output = NRF_RTC0->COUNTER;
            break;
    }
    return output;
}
```

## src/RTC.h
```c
/*
        Real Time Clock(RTC) Library
        Author : Seonguk Jeong
        Created at : 2023-10-12
        Updated at : 2023-10-12
        Target : nRF52 Series
*/
#pragma once
#include <stdint.h>
#include <string.h>
#include <zephyr/kernel.h>

#define RTC0 0x00
#define RTC1 0x01
#define RTC2 0x02
#define RTC_COMPARE0 0x00
#define RTC_COMPARE1 0x01
#define RTC_COMPARE2 0x02
#define RTC_COMPARE3 0x03
#define RTC_NO_INTERRUPT 0x00
#define RTC_INTERRUPT_TICK 0x01
#define RTC_INTERRUPT_OVRFLW (0x01 << 1)
#define RTC_INTERRUPT_COMPARE0 (0x01 << 16)
#define RTC_INTERRUPT_COMPARE1 (0x01 << 17)
#define RTC_INTERRUPT_COMPARE2 (0x01 << 18)
#define RTC_INTERRUPT_COMPARE3 (0x01 << 19)
#define RTC_COMPARE0    0x00
#define RTC_COMPARE1    0x01
#define RTC_COMPARE2    0x02
#define RTC_COMPARE3    0x03

struct RTC_CONFIG{
    uint8_t channel;
    uint16_t prescaler;
};


class RTC{
    private:
        void setPrescaler();
        RTC_CONFIG CONF;
    public:
        void Init(RTC_CONFIG CONFIG);
        void Start();
        void Stop();
        void setInterrupt(uint32_t interrupt);
        void clearInterrupt( uint32_t interrupt);
        void setEvent(uint32_t event);
        void clearEvent(uint32_t event);
        void setCompare(uint8_t comp_no, uint32_t cc);
        uint32_t getCounter();
};
```

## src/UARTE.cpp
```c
#include "UARTE.h"

// Static variables
uint8_t UARTE::UARTE_TX_BUFF[255] = {0};
uint8_t UARTE::UARTE_RX_BUFF[255] = {0};

void UARTE::Init(UARTE_CONFIG CONFIG){
	// Initialize UARTE
    NRF_UARTE0->ENABLE = 0;
    NRF_UARTE0->PSEL.TXD = CONFIG.PIN_TX;
	NRF_UARTE0->PSEL.RXD = CONFIG.PIN_RX;
	NRF_UARTE0->BAUDRATE = CONFIG.BAUD;
	NRF_UARTE0->CONFIG = 0x00;

	// Set buffer
	NRF_UARTE0->TXD.PTR = (uint32_t)&UARTE_TX_BUFF;
	NRF_UARTE0->RXD.PTR = (uint32_t)&UARTE_RX_BUFF;
	NRF_UARTE0->ENABLE = 8;

	// Copy configuration structure
	memcpy(&CONF, &CONFIG, sizeof(CONFIG));
}

void UARTE::Clear(){
	NRF_UARTE0->ENABLE = 0;
}

void UARTE::Write(uint8_t *data, uint8_t length){
    // for data send
	memset(UARTE_TX_BUFF, 0, 255);
	memcpy(UARTE_TX_BUFF, data, length);
	NRF_UARTE0->TXD.MAXCNT = length;
	NRF_UARTE0->TASKS_STARTTX = 1;
	while(!NRF_UARTE0->EVENTS_ENDTX){}
	NRF_UARTE0->EVENTS_ENDTX = 0;
	NRF_UARTE0->TASKS_STOPTX = 1;
}

void UARTE::startRx(uint8_t buf_length){
	NRF_UARTE0->RXD.MAXCNT = buf_length;
	NRF_UARTE0->TASKS_STARTRX = 1;
}

void UARTE::setInterrupt(uint32_t interrupt){
	NRF_UARTE0->INTENSET = interrupt;
}

void UARTE::clearInterrupt(uint32_t interrupt){
	NRF_UARTE0->INTENCLR = interrupt;
}

void UARTE::setShorts(uint32_t shorts){
	NRF_UARTE0->SHORTS = shorts;
}

void UARTE::clearShorts(uint32_t shorts){
	NRF_UARTE0->SHORTS = 0x00;
}

void UARTE::clearEvents(){
	NRF_UARTE0->EVENTS_CTS = 0;
	NRF_UARTE0->EVENTS_NCTS = 0;
	NRF_UARTE0->EVENTS_RXDRDY = 0;
	NRF_UARTE0->EVENTS_ENDRX = 0;
	NRF_UARTE0->EVENTS_TXDRDY = 0;
	NRF_UARTE0->EVENTS_ENDTX = 0;
	NRF_UARTE0->EVENTS_ERROR = 0;
	NRF_UARTE0->EVENTS_RXTO = 0;
	NRF_UARTE0->EVENTS_RXSTARTED = 0;
	NRF_UARTE0->EVENTS_TXSTARTED = 0;
	NRF_UARTE0->EVENTS_TXSTOPPED = 0;
}

void UARTE::clearRxBuffers(){
	memset(UARTE_RX_BUFF, 0x00, sizeof(UARTE_RX_BUFF));
}
```

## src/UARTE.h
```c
/*
        UARTE Library
        Author : Seonguk Jeong
        Created at : 2023-10-12
        Updated at : 2023-10-12
        Target : nRF52 Series
*/
#pragma once
#include <stdint.h>
#include <string.h>
#include <zephyr/kernel.h>

#define UARTE_BAUDRATE_9600	        0x00275000
#define UARTE_BAUDRATE_14400	    0x003AF000
#define UARTE_BAUDRATE_19200	    0x004EA000
#define UARTE_BAUDRATE_28800	    0x0075C000
#define UARTE_BAUDRATE_38400	    0x009D0000
#define UARTE_BAUDRATE_57600	    0x00EB0000
#define UARTE_BAUDRATE_76800	    0x013A9000
#define UARTE_BAUDRATE_115200	    0x01D60000
#define UARTE_BAUDRATE_230400	    0x03B00000
#define UARTE_NO_INTERRUPT			0x00
#define UARTE_INTERRUPT_CTS			0x01
#define UARTE_INTERRUPT_NCTS		(0x01 << 1)
#define UARTE_INTERRUPT_RXDRDY		(0x01 << 2)
#define UARTE_INTERRUPT_ENDRX		(0x01 << 4)
#define UARTE_INTERRUPT_TXDRDY		(0x01 << 7)
#define UARTE_INTERRUPT_ENDTX		(0x01 << 8)
#define UARTE_INTERRUPT_ERROR		(0x01 << 9)
#define UARTE_INTERRUPT_RXTO		(0x01 << 17)
#define UARTE_INTERRUPT_RXSTARTED	(0x01 << 19)
#define UARTE_INTERRUPT_TXSTARTED	(0x01 << 20)
#define UARTE_INTERRUPT_TXSTOPPED	(0x01 << 22)
#define UARTE_SHORTS_ENDRX_STARTRX	(1 << 5)
#define UARTE_SHORTS_ENDRX_STOPRX	(1 << 6)

struct UARTE_CONFIG{
    uint32_t PIN_RX;
    uint32_t PIN_TX;
    uint32_t BAUD;
};

class UARTE{
    private:
        static uint8_t UARTE_TX_BUFF[255], UARTE_RX_BUFF[255];
        UARTE_CONFIG CONF;
        void clearEvents();
    public:
        void Init(UARTE_CONFIG CONFIG);
        void Clear();
        void Write(uint8_t *data, uint8_t length);
        void startRx(uint8_t buf_length);
        void setInterrupt(uint32_t interrupt);
        void clearInterrupt(uint32_t interrupt);
        void setShorts(uint32_t shorts);
        void clearShorts(uint32_t shorts);
        void clearRxBuffers();
};
```
